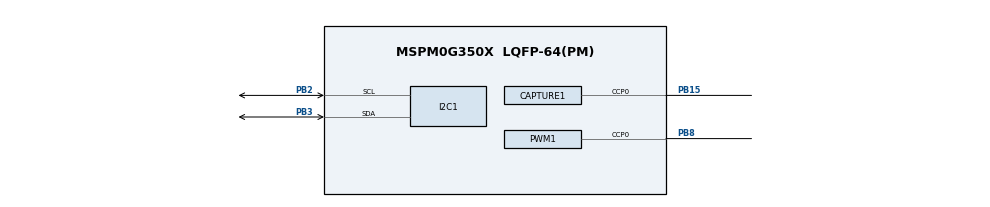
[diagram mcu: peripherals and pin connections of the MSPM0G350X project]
/**
 * @cliArgs --device "MSPM0G350X" --part "Default" --package "LQFP-64(PM)" --product "mspm0_sdk@2.04.00.06"
 * @versions {"tool":"1.23.0+4000"}
 */

/**
 * Import the modules used in this configuration.
 */
const CAPTURE  = scripting.addModule("/ti/driverlib/CAPTURE", {}, false);
const CAPTURE1 = CAPTURE.addInstance();
const I2C      = scripting.addModule("/ti/driverlib/I2C", {}, false);
const I2C1     = I2C.addInstance();
const PWM      = scripting.addModule("/ti/driverlib/PWM", {}, false);
const PWM1     = PWM.addInstance();
const SYSCTL   = scripting.addModule("/ti/driverlib/SYSCTL");

/**
 * Write custom configuration values to the imported modules.
 */
const divider7       = system.clockTree["PLL_PDIV"];
divider7.divideValue = 2;

const divider9       = system.clockTree["UDIV"];
divider9.divideValue = 2;

const multiplier2         = system.clockTree["PLL_QDIV"];
multiplier2.multiplyValue = 5;

const mux8       = system.clockTree["HSCLKMUX"];
mux8.inputSelect = "HSCLKMUX_SYSPLL2X";

CAPTURE1.$name                              = "CAPTURE_ULTRASONIC";
CAPTURE1.timerClkPrescale                   = 80;
CAPTURE1.timerPeriod                        = "50 ms";
CAPTURE1.captMode                           = "PULSE_WIDTH_UP";
CAPTURE1.peripheral.ccp0Pin.$assign         = "PB15";
CAPTURE1.ccp0PinConfig.hideOutputInversion  = scripting.forceWrite(false);
CAPTURE1.ccp0PinConfig.onlyInternalResistor = scripting.forceWrite(false);
CAPTURE1.ccp0PinConfig.passedPeripheralType = scripting.forceWrite("Digital");
CAPTURE1.ccp0PinConfig.$name                = "ti_driverlib_gpio_GPIOPinGeneric3";

const Board = scripting.addModule("/ti/driverlib/Board", {}, false);

I2C1.$name                             = "I2C_OLED";
I2C1.basicEnableController             = true;
I2C1.basicControllerStandardBusSpeed   = "Fast";
I2C1.peripheral.sdaPin.$assign         = "PB3";
I2C1.peripheral.sclPin.$assign         = "PB2";
I2C1.sdaPinConfig.hideOutputInversion  = scripting.forceWrite(false);
I2C1.sdaPinConfig.onlyInternalResistor = scripting.forceWrite(false);
I2C1.sdaPinConfig.passedPeripheralType = scripting.forceWrite("Digital");
I2C1.sdaPinConfig.$name                = "ti_driverlib_gpio_GPIOPinGeneric0";
I2C1.sclPinConfig.hideOutputInversion  = scripting.forceWrite(false);
I2C1.sclPinConfig.onlyInternalResistor = scripting.forceWrite(false);
I2C1.sclPinConfig.passedPeripheralType = scripting.forceWrite("Digital");
I2C1.sclPinConfig.$name                = "ti_driverlib_gpio_GPIOPinGeneric1";

PWM1.$name                              = "PWM_ULTRASONIC";
PWM1.clockPrescale                      = 250;
PWM1.timerCount                         = 64000;
PWM1.timerStartTimer                    = true;
PWM1.ccIndex                            = [0];
PWM1.PWM_CHANNEL_0.$name                = "ti_driverlib_pwm_PWMTimerCC0";
PWM1.PWM_CHANNEL_0.dutyCycle            = 50;
PWM1.ccp0PinConfig.direction            = scripting.forceWrite("OUTPUT");
PWM1.ccp0PinConfig.hideOutputInversion  = scripting.forceWrite(false);
PWM1.ccp0PinConfig.onlyInternalResistor = scripting.forceWrite(false);
PWM1.ccp0PinConfig.passedPeripheralType = scripting.forceWrite("Digital");
PWM1.ccp0PinConfig.$name                = "ti_driverlib_gpio_GPIOPinGeneric2";
PWM1.peripheral.ccp0Pin.$assign         = "PB8";

SYSCTL.forceDefaultClkConfig = true;
SYSCTL.clockTreeEn           = true;
scripting.suppress("For best practices when the CPUCLK is running at 32MHz and above, clear the flash status bit using DL_FlashCTL_executeClearStatus\\(\\) before executing any flash operation\\. Otherwise there may be false positives\\.", SYSCTL);

/**
 * Pinmux solution for unlocked pins/peripherals. This ensures that minor changes to the automatic solver in a future
 * version of the tool will not impact the pinmux you originally saw.  These lines can be completely deleted in order to
 * re-solve from scratch.
 */
CAPTURE1.peripheral.$suggestSolution       = "TIMG7";
Board.peripheral.$suggestSolution          = "DEBUGSS";
Board.peripheral.swclkPin.$suggestSolution = "PA20";
Board.peripheral.swdioPin.$suggestSolution = "PA19";
I2C1.peripheral.$suggestSolution           = "I2C1";
PWM1.peripheral.$suggestSolution           = "TIMA0";
